# HM1030 register map
File version: 0.1
Registers are 32-bit, read-write, reset 0x0 unless marked. A register's access mark holds for its fields unless they carry their own. Offsets are from the block's base; [hi:lo] are bit positions; lines under a group give offsets from that group; {n}, {i} and the like mark numbered series.

## PWMPLUS0 — Registers group
Base 0x400B4000
Same registers: PWMPLUS1 0x400B4800
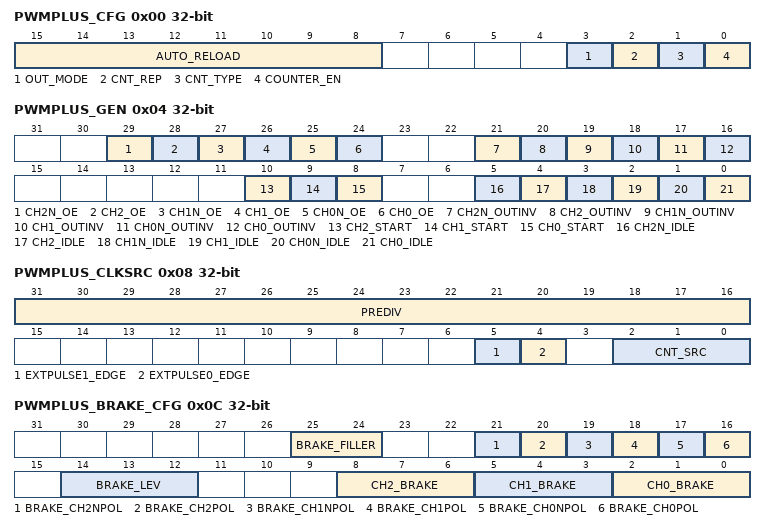
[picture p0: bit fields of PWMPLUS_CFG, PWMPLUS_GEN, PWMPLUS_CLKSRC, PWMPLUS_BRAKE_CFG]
0x00 PWMPLUS_CFG — PWMPLUS配置寄存器
  [15:8] AUTO_RELOAD — 自动装载寄存器，表示周期溢出多少次后自动装载一次周期值、比较值、死区值和TRIGGER值。
  [3] OUT_MODE — PWM输出模式
  [2] CNT_REP — PWM计数器循环方式
  [1] CNT_TYPE — PWM计数器行为方式
  [0] COUNTER_EN — 计数器使能寄存器
0x04 PWMPLUS_GEN — PWMPLUS通道波形生成寄存器
  [29] CH2N_OE — CH2N通道波形输出使能
  [28] CH2_OE — CH2通道波形输出使能
  [27] CH1N_OE — CH1N通道波形输出使能
  [26] CH1_OE — CH1通道波形输出使能
  [25] CH0N_OE — CH0N通道波形输出使能
  [24] CH0_OE — CH0通道波形输出使能
  [21] CH2N_OUTINV — CH2N通道输出状态选择
  [20] CH2_OUTINV — CH2通道输出状态选择
  [19] CH1N_OUTINV — CH1N通道输出状态选择
  [18] CH1_OUTINV — CH1通道输出状态选择
  [17] CH0N_OUTINV — CH0N通道输出状态选择
  [16] CH0_OUTINV — CH0通道输出状态选择
  [10] CH2_START — 原始CH2通道计数开始时输出状态值
  [9] CH1_START — 原始CH1通道计数开始时输出状态值
  [8] CH0_START — 原始CH0通道开始计数时输出状态值
  [5] CH2N_IDLE — 原始CH2N通道空闲时输出状态值
  [4] CH2_IDLE — 原始CH2通道空闲时输出状态值
  [3] CH1N_IDLE — 原始CH1N通道空闲时输出状态值
  [2] CH1_IDLE — 原始CH1通道空闲时输出状态值
  [1] CH0N_IDLE — 原始CH0N通道空闲时输出状态值
  [0] CH0_IDLE — 原始CH0通道空闲时输出状态值
0x08 PWMPLUS_CLKSRC — PWMPLUS时钟源和分频配置寄存器
  [31:16] PREDIV — 内部预分频时钟频率选择。
  [5] EXTPULSE1_EDGE — Extpulse1作为计数时钟时边沿选择控制
  [4] EXTPULSE0_EDGE — Extpulse0作为计数时钟时边沿选择控制
  [2:0] CNT_SRC — PWMPLUS计数器计数时钟选择
0x0C PWMPLUS_BRAKE_CFG — PWMPLUS刹车配置寄存器
  [25:24] BRAKE_FILLER — 刹车信号数字滤波控制
  [21] BRAKE_CH2NPOL — 刹车时CH2N输出电平选择
  [20] BRAKE_CH2POL — 刹车时CH2输出电平选择
  [19] BRAKE_CH1NPOL — 刹车时CH1N输出电平选择
  [18] BRAKE_CH1POL — 刹车时CH1输出电平选择
  [17] BRAKE_CH0NPOL — 刹车时CH0N输出电平选择
  [16] BRAKE_CH0POL — 刹车时CH0输出电平选择
  [14:12] BRAKE_LEV — 刹车有效电平选择
  [8:6] CH2_BRAKE — CH2/CH2N刹车控制选择
  [5:3] CH1_BRAKE — CH1/CH1N刹车控制选择
  [2:0] CH0_BRAKE — CH0/CH0N刹车控制选择
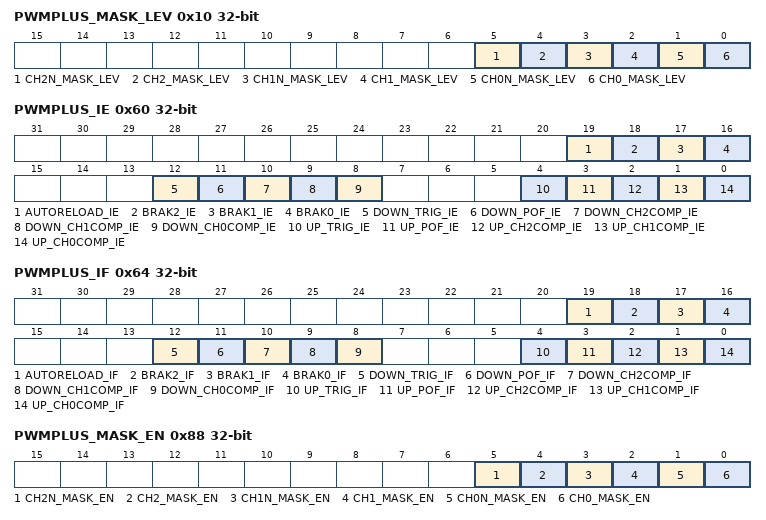
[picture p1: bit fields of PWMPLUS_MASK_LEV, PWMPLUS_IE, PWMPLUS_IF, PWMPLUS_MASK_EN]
0x10 PWMPLUS_MASK_LEV — PWMPLUS强制输出电平选择寄存器
  [5] CH2N_MASK_LEV — CH2N通道屏蔽电平选择
  [4] CH2_MASK_LEV — CH2通道屏蔽电平选择
  [3] CH1N_MASK_LEV — CH1N通道屏蔽电平选择
  [2] CH1_MASK_LEV — CH1通道屏蔽电平选择
  [1] CH0N_MASK_LEV — CH0N通道屏蔽电平选择
  [0] CH0_MASK_LEV — CH0通道屏蔽电平选择
0x1C PWMPLUS_PERIOD — PWMPLUS计数器周期值寄存器
  [15:0] PERIOD — PWMPLUS周期配置寄存器。
{0x20+4i} PWMPLUS_CH{i}_COMP (i=0..2) — PWMPLUS通道{i}翻转点配置寄存器
  [15:0] CH{i}_COMP — CH{i}/CH{i}N翻转点配置寄存器。
{0x30+4i} PWMPLUS_CH{i}_DT (i=0..2) — PWMPLUS通道{i}死区长度配置寄存器
  [9:0] CH{i}_DT — CH{i}/CH{i}N死区长度配置寄存器
0x40 PWMPLUS_TRIG_COMP — PWMPLUS内部触发比较值寄存器
  [15:0] TRIG_COMP — 内部触发点配置寄存器
0x44 PWMPLUS_TRIG_CFG — PWMPLUS内部触发配置寄存器
  [3:0] TRIGOUT0_SEL — 输出的trigger0信号功能选择
0x60 PWMPLUS_IE — PWMPLUS中断使能寄存器
  [19] AUTORELOAD_IE — 自动装载中断使能
  [18] BRAK2_IE — 刹车2中断使能
  [17] BRAK1_IE — 刹车1中断使能
  [16] BRAK0_IE — 刹车0中断使能
  [12] DOWN_TRIG_IE — 向下计数达到TRIGGER触发点中断使能
  [11] DOWN_POF_IE — 向下计数周期溢出中断使能
  [10] DOWN_CH2COMP_IE — 向下计数CH2到达翻转点中断使能
  [9] DOWN_CH1COMP_IE — 向下计数CH1到达翻转点中断使能
  [8] DOWN_CH0COMP_IE — 向下计数CH0到达翻转点中断使能
  [4] UP_TRIG_IE — 向上计数达到TRIGGER触发点中断使能
  [3] UP_POF_IE — 向上计数周期溢出中断使能
  [2] UP_CH2COMP_IE — 向上计数CH2到达翻转点中断使能
  [1] UP_CH1COMP_IE — 向上计数CH1到达翻转点中断使能
  [0] UP_CH0COMP_IE — 向上计数CH0到达翻转点中断使能
0x64 PWMPLUS_IF — PWMPLUS中断状态寄存器
  [19] AUTORELOAD_IF — 自动装载中断状态
  [18] BRAK2_IF — 刹车2中断状态
  [17] BRAK1_IF — 刹车1中断状态
  [16] BRAK0_IF — 刹车0中断状态
  [12] DOWN_TRIG_IF — 向下计数达到TRIGGER触发点中断状态
  [11] DOWN_POF_IF — 向下计数周期溢出中断状态
  [10] DOWN_CH2COMP_IF — 向下计数CH2到达翻转点中断状态
  [9] DOWN_CH1COMP_IF — 向下计数CH1到达翻转点中断状态
  [8] DOWN_CH0COMP_IF — 向下计数CH0到达翻转点中断状态
  [4] UP_TRIG_IF — 向上计数达到TRIGGER触发点中断状态
  [3] UP_POF_IF — 向上计数周期溢出中断状态
  [2] UP_CH2COMP_IF — 向上计数CH2到达翻转点中断状态
  [1] UP_CH1COMP_IF — 向上计数CH1到达翻转点中断状态
  [0] UP_CH0COMP_IF — 向上计数CH0到达翻转点中断状态
0x84 PWMPLUS_SWLOAD — PWMPLUS配置寄存器软件加载寄存器
  [0] SWLOAD — PWM配置寄存器软件LOAD控制位
0x88 PWMPLUS_MASK_EN — PWMPLUS屏蔽使能控制寄存器
  [5] CH2N_MASK_EN — CH2N通道屏蔽使能
  [4] CH2_MASK_EN — CH2通道屏蔽使能
  [3] CH1N_MASK_EN — CH1N通道屏蔽使能
  [2] CH1_MASK_EN — CH1通道屏蔽使能
  [1] CH0N_MASK_EN — CH0N通道屏蔽使能
  [0] CH0_MASK_EN — CH0通道屏蔽使能
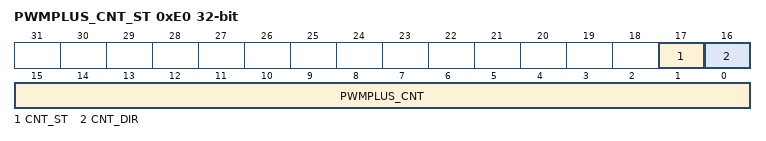
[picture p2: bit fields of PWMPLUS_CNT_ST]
0xE0 PWMPLUS_CNT_ST ro — PWMPLUS计数器状态寄存器
  [17] CNT_ST rw — PWM计数器工作状态
  [16] CNT_DIR rw — PWM计数器当前计数方向
  [15:0] PWMPLUS_CNT rw — PWM计数器当前计数值寄存器
0xE4 PWMPLUS_BRAKE_ST — PWMPLUS刹车状态寄存器
  [1:0] BRAKE_ST — 刹车输入信号当前状态
